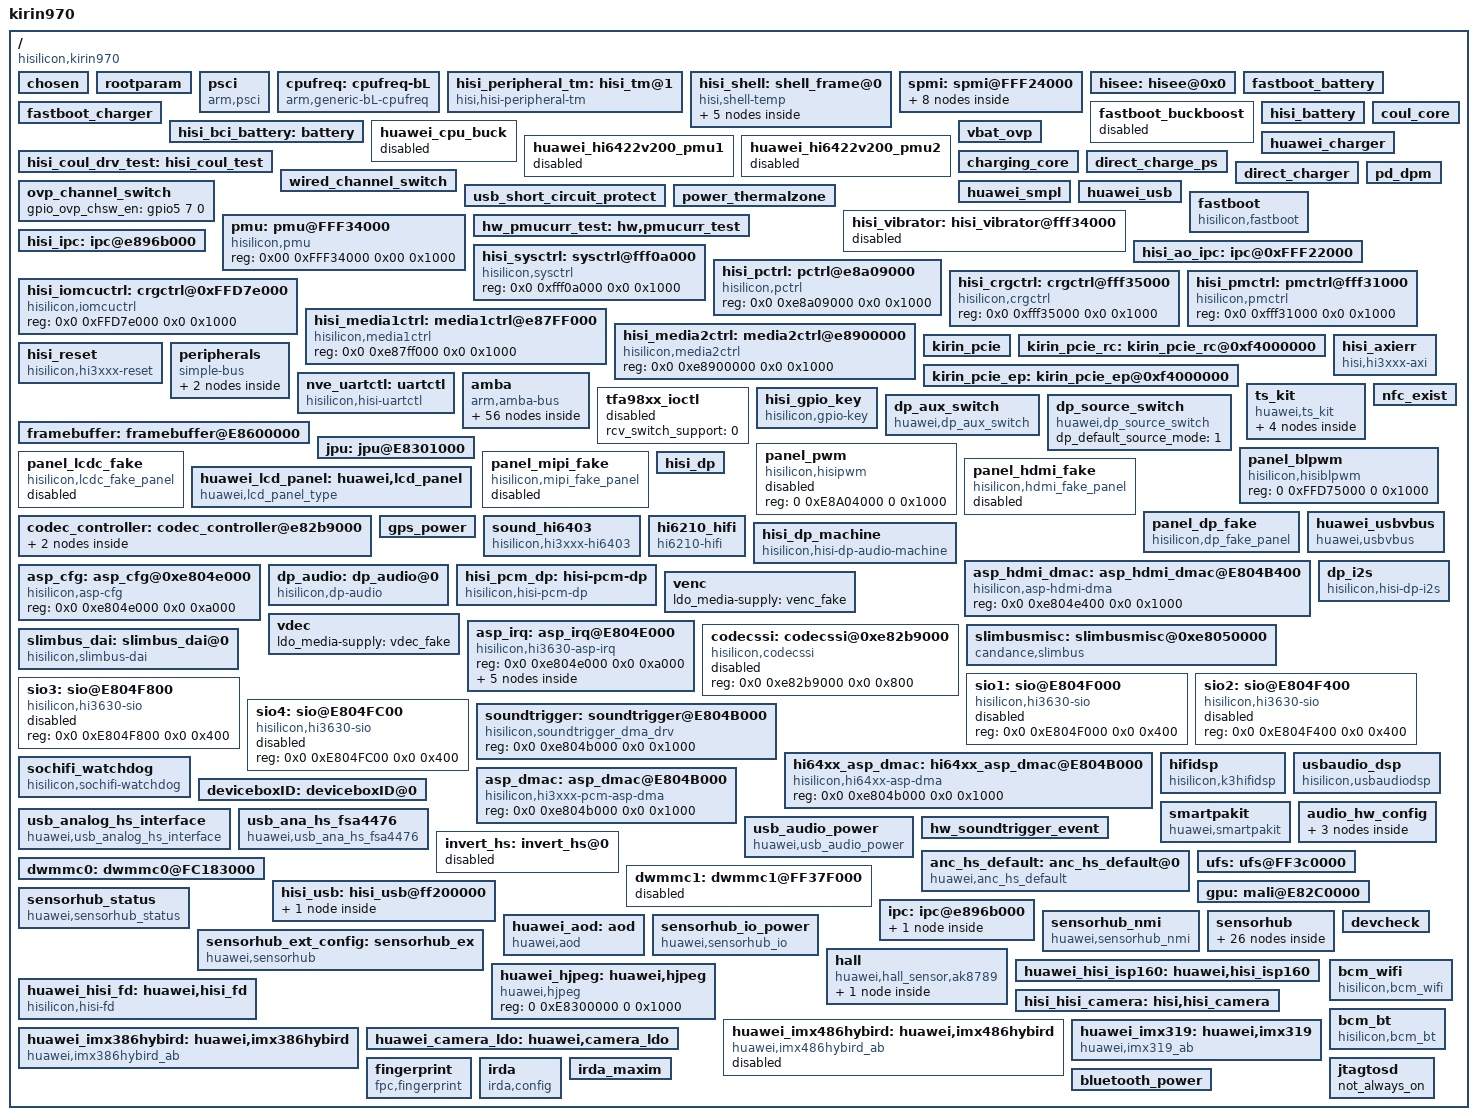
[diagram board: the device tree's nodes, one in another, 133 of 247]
/**
 * Copyright (C) 2014 Hisilicon Ltd.
 *
 *  This program is free software; you can redistribute it and/or modify
 *  it under the terms of the GNU General Public License version 2 as
 *  publishhed by the Free Software Foundation.
 */

/dts-v1/;
/include/ "fastboot.dtsi"
/include/ "BLANC_TUGL_V1_pin.dtsi"
/include/ "kirin970_cci.dtsi"
/include/ "kirin970_gic.dtsi"
/include/ "kirin970_timer.dtsi"
/include/ "kirin970_clock_cs.dtsi"
/include/ "kirin970_peri_dvfs_volt_cs.dtsi"
/include/ "kirin970_peri_dvfs_cs.dtsi"
/include/ "kirin970_isp_cs.dtsi"
/include/ "kirin970_powerip_cs.dtsi"
/include/ "hisi_freq_autodown.dtsi"
/include/ "kirin970.dtsi"
/include/ "kirin970_lowpm.dtsi"
/include/ "kirin970_i2c.dtsi"
/include/ "kirin970_gpio_cs.dtsi"
/include/ "kirin970_pinctrl_cs.dtsi"
/include/ "hisi_64xx_codec.dtsi"
/include/ "BLANC_TUGL_V1_hi6402_pin.dtsi"
/include/ "huawei_pmucurr_test.dtsi"
/include/ "hisi_bci_battery.dtsi"
/include/ "hisi_battery.dtsi"
/include/ "huawei_charger.dtsi"
/include/ "hisi_coul_spmi.dtsi"
/include/ "kirin970_soft_isc.dtsi"
/include/ "fastboot_battery.dtsi"
/include/ "fastboot_charger.dtsi"
/include/ "usb_short_circuit_protect.dtsi"
/include/ "desayatl_3900_39k_4400.dtsi"
/include/ "scudlg_3900_200k_4400_25.dtsi"
/include/ "sunwodasony_3900_110k_4400_15.dtsi"
/include/ "kirin970_thermal.dtsi"
/include/ "kirin970_pd.dtsi"
/include/ "fastboot_charger.dtsi"
/include/ "hisi_power_ip_test.dtsi"
/include/ "kirin970_framebuffer.dtsi"
/include/ "hisi_6421v600_pmic_led_spmi.dtsi"
/include/ "kirin970_coresight.dtsi"
/include/ "hisi_rtc_spmi.dtsi"
/include/ "modem/hisi_modem_balong.dtsi"
/include/ "hisi_soundtrigger_event.dtsi"
/include/ "huawei_audio.dtsi"
/include/ "huawei_smartpa.dtsi"
/include/ "kirin970_noc.dtsi"
/include/ "kirin970_dma64.dtsi"
/include/ "huawei_gps.dtsi"
/include/ "kirin970_trustedcore.dtsi"
/include/ "kirin970_jpu.dtsi"
/include/ "kirin970_ics_cs.dtsi"
/include/ "kirin970_perfstat_cs.dtsi"
/include/ "kirin970_cpu_cs.dtsi"
/include/ "huawei_connectivity.dtsi"
/include/ "huawei_devdetect.dtsi"
/include/ "huawei_hall_inputhub.dtsi"
/include/ "huawei_irda.dtsi"
/include/ "huawei_usbpd.dtsi"
/include/ "huawei_usb_vbus.dtsi"
/include/ "huawei_bluetooth.dtsi"
/include/ "hisi_sim_hotplug.dtsi"
/include/ "lcdkit/default/devkit_lcd.dtsi"
/include/ "lcdkit/blanc_tugl/devkit_lcd.dtsi"
/include/ "huawei_usbswitch.dtsi"
/include/ "huawei_bastet.dtsi"

/ {
	#address-cells = <2>;
	#size-cells = <2>;
	model = "kirin970";
	compatible = "hisilicon,kirin970";
	interrupt-parent = <&gic>;
	hisi,boardid = <6 4 5 0>;
	hisi,boardname = "BLANC_TUGL_V1";
	hisi,modem_id = <0x39010000>;
	hisi,product_id = <0x39010000>;
	hisi,product_name = "BLANC-AL00";
	hisi,camera_arch_csudp = "platform_cs_udp";

	chosen: chosen {};

	rootparam: rootparam {
	};


	psci: psci {
                compatible      = "arm,psci";
        };

	/* cpufreq  device */
	cpufreq: cpufreq-bL {
		compatible = "arm,generic-bL-cpufreq";
		status = "ok";
	};

	hisi_peripheral_tm: hisi_tm@1 {
		compatible = "hisi,hisi-peripheral-tm";
		hisi,peripheral_sensors = <8>;

		hisi,detect_system_h_tm_chanel = <7>;
		hisi,detect_system_h_tm_ntc = "austin_hkadc_soc_temp_table";
		hisi,detect_system_h_tm_state = "enable";
		hisi,detect_system_h_throttling = <53>;
		hisi,detect_system_h_shutdown = <55>;
		hisi,detect_system_h_below_vr_min = <53>;
		hisi,detect_system_h_over_skin = <12>;

		hisi,detect_flash_led_tm_chanel = <3>;
		hisi,detect_flash_led_tm_ntc = "austin_hkadc_soc_temp_table";
		hisi,detect_flash_led_tm_state = "enable";

		hisi,detect_charger_tm_chanel = <5>;
		hisi,detect_charger_tm_ntc = "austin_hkadc_soc_temp_table";
		hisi,detect_charger_tm_state = "enable";

		hisi,detect_pa_0_tm_chanel = <4>;
		hisi,detect_pa_0_tm_ntc = "austin_hkadc_pa_temp_table";
		hisi,detect_pa_0_tm_state = "enable";

		hisi,detect_pa_1_tm_chanel = <9>;
		hisi,detect_pa_1_tm_ntc = "austin_hkadc_pa_temp_table";
		hisi,detect_pa_1_tm_state = "enable";

		hisi,detect_dcxo0_tm_chanel = <15>;
		hisi,detect_dcxo0_tm_ntc = "austin_hkadc_adc_temp_table";
		hisi,detect_dcxo0_tm_state = "enable";

		hisi,detect_shell_tm_chanel = <7>;
		hisi,detect_shell_tm_ntc = "austin_hkadc_soc_temp_table";
		hisi,detect_shell_tm_state = "disable";

		hisi,detect_charger1_tm_chanel = <4>;
		hisi,detect_charger1_tm_ntc = "austin_hkadc_soc_temp_table";
		hisi,detect_charger1_tm_state = "disable";

		status = "ok";
	};

	hisi_shell: shell_frame@0 {
		compatible = "hisi,shell-temp";
		interval = <5000>;
		bias = <50000>;
		count = <6>;
		status = "ok";

		sensors {
			sensor0 {
				type = "system_h";
				coef = "15157","5997","4051","4534","8584","30816";
			};

			sensor1 {
				type = "charger";
				coef = "-761","-2276","-3227","-1293","-2952","-10036";
			};

			sensor2 {
				type = "pa_0";
				coef = "30555","9209","7077","8095","10650","28721";
			};

			sensor3 {
				type = "dcxo0";
				coef = "-5456","-5990","-6211","-6711","-9098","-17481";
			};
		};
	};

	spmi: spmi@FFF24000 {
		pmic: pmic@0 {
			pmic_led: pmic_led@a0 {
				status = "ok";
			};

			pmic_rtc: pmic_rtc@a0 {
				status = "ok";
			};

			ponkey: ponkey@b1 {
				status = "ok";
			};

			pmic_mntn: pmic_mntn@a0 {
				status = "ok";
			};

			hi6421v600_coul_spmi: hi6421v600_coul_spmi@1 {
                                 status = "ok";
                        };
		};
	};

	hisee: hisee@0x0 {
	};

	fastboot_battery: fastboot_battery {
		status = "ok";
	};

	fastboot_charger: fastboot_charger {
		status = "ok";
	};

	fastboot_buckboost: fastboot_buckboost {
		status = "disabled";
	};

	hisi_battery: hisi_battery {
		status = "ok";
	};

	hisi_bci_battery: battery {
		status = "ok";
	};

	coul_core: coul_core {
		status = "ok";
	};

	huawei_cpu_buck: huawei_cpu_buck {
		status = "disabled";
	};

	huawei_hi6422v200_pmu1: huawei_hi6422v200_pmu1 {
		status = "disabled";
	};

	huawei_hi6422v200_pmu2: huawei_hi6422v200_pmu2 {
		status = "disabled";
	};

	hisi_coul_drv_test: hisi_coul_test {
		status = "ok";
	};

	huawei_charger: huawei_charger {
		status = "ok";
	};

	vbat_ovp: vbat_ovp {
		status = "ok";
	};

	charging_core: charging_core {
		status = "ok";
		iterm = <160>;
		iin_usb = <470>;
		ichg_usb = <500>;
		ichg_fcp = <3500>;
		iin_fcp = <2000>;
		ichg_ac = <2100>;
		iin_ac = <2000>;
		inductance_para =
			"-32767", "15", "1900", "0",
			"15", "32767", "1900", "0";
	};
	direct_charge_ps: direct_charge_ps {
		boost_5v_support_scp_power = <1>;
		bst_ctrl_use_common_gpio = <1>;
		is_need_bst_ctrl = <1>;
		status = "ok";
	};
	direct_charger: direct_charger{
		use_5A = <1>;
		volt_para =
			"4100", "5150", "4650",
			"4250", "4650", "2800",
			"4360", "2800", "1200";
		compensate_r = <20>;
		cc_cable_detect_enable = <1>;
		full_path_res_max = <140>;
		scp_work_on_charger = <1>;
		standard_cable_full_path_res_max = <200>;
		temp_para =
			"-32767", "10", "0",
			"10", "45", "5150",
			"45", "32767", "0";
		status = "ok";
	};
	wired_channel_switch: wired_channel_switch {
		status = "ok";
	};
	ovp_channel_switch: ovp_channel_switch {
		gpio_ovp_chsw_en = <&gpio5 7 0>;
		status = "ok";
	};
	huawei_smpl: huawei_smpl {
		status = "ok";
	};

	usb_short_circuit_protect: usb_short_circuit_protect {
		status = "ok";
	};

	power_thermalzone: power_thermalzone {
		status = "ok";
	};

	pd_dpm: pd_dpm {
		uart_use_sbu = <1>;
		uart_rx_gpio = <&gpio4 5 0>;
		uart_tx_gpio = <&gpio4 6 0>;
		abnormal_cc_detection = <1>;
		status = "ok";
	};

	huawei_usb: huawei_usb {
		status = "ok";
	};

	hisi_vibrator: hisi_vibrator@fff34000 {
		status = "disabled";
	};

	fastboot: fastboot {
		compatible = "hisilicon,fastboot";
	};

	pmu: pmu@FFF34000 {
		compatible = "hisilicon,pmu";
		reg = <0x00 0xFFF34000 0x00 0x1000>;
		status = "ok";
	};

	hw_pmucurr_test: hw,pmucurr_test {
		status = "ok";
	};

	hisi_ipc: ipc@e896b000 {
		status = "ok";
	};

	hisi_ao_ipc: ipc@0xFFF22000 {
		status = "ok";
	};

        hisi_sysctrl: sysctrl@fff0a000 {
                compatible = "hisilicon,sysctrl";
                reg = <0x0 0xfff0a000 0x0 0x1000>;
                status = "ok";
        };

        hisi_pctrl: pctrl@e8a09000 {
                compatible = "hisilicon,pctrl";
                reg = <0x0 0xe8a09000 0x0 0x1000>;
                status = "ok";
        };

        hisi_crgctrl: crgctrl@fff35000 {
                compatible = "hisilicon,crgctrl";
                reg = <0x0 0xfff35000 0x0 0x1000>;
                status = "ok";
        };

        hisi_iomcuctrl: crgctrl@0xFFD7e000 {
                compatible = "hisilicon,iomcuctrl";
                reg = <0x0 0xFFD7e000 0x0 0x1000>;
                status = "ok";
	};

        hisi_pmctrl: pmctrl@fff31000 {
                compatible = "hisilicon,pmctrl";
                reg = <0x0 0xfff31000 0x0 0x1000>;
                status = "ok";
        };

        hisi_media1ctrl: media1ctrl@e87FF000 {
                compatible = "hisilicon,media1ctrl";
                reg = <0x0 0xe87ff000 0x0 0x1000>;
                status = "ok";
        };

        hisi_media2ctrl: media2ctrl@e8900000 {
                compatible = "hisilicon,media2ctrl";
                reg = <0x0 0xe8900000 0x0 0x1000>;
                status = "ok";
        };

	kirin_pcie: kirin_pcie {
	};

	kirin_pcie_rc: kirin_pcie_rc@0xf4000000 {
		reg =  <0x0 0xf4000000 0x0 0x1000000>, <0x0 0xfc180000 0x0 0x1000>, <0x0 0xfc000000 0x0 0x80000>, <0x0 0xF4000000 0 0x2000>;
		status = "ok";
	};

	kirin_pcie_ep: kirin_pcie_ep@0xf4000000 {
		reg =  <0x0 0xf4000000 0x0 0x1000000>, <0x0 0xfc180000 0x0 0x1000>, <0x0 0xfc000000 0x0 0x80000>, <0x0 0xF4000000 0 0x2000>;
	};

	hisi_axierr: hisi_axierr {
	        compatible = "hisi,hi3xxx-axi";
	        status = "ok";
        };

	hisi_reset: hisi_reset {
		compatible = "hisilicon,hi3xxx-reset";
		status = "ok";
	};

	peripherals: peripherals {
		compatible = "simple-bus";
		ranges = <0x0 0x00000000 0x0 0xffffffff>;

		clk6250khz: clk6250khz {
			compatible = "fixed-clock";
		};
/*
		clk4800khz: clk4800khz {
			compatible = "fixed-clock";
		};
*/
		dma0: dma@fdf30000 {
			status = "ok";
		};
	};

	nve_uartctl: uartctl {
		compatible = "hisilicon,hisi-uartctl";
	};

	amba: amba {
		compatible = "arm,amba-bus";
		ranges;

		/*rtc0: rtc@FFF04000 {
				compatible = "arm,rtc-pl031", "arm,primecell";
				reg = <0xfff04000 0x1000>;
				status = "ok";
		};*/

		/*rtc1: rtc@FFF05000 {
				compatible = "arm,rtc-pl031", "arm,primecell";
				reg = <0xfff05000 0x1000>;
				status = "ok";
		};*/

		watchdog0 {
			compatible = "arm,sp805", "arm,primecell";
			reg = <0x0 0xe8a06000 0x0 0x1000>;
			default-timeout = <24>;
			interrupts = <0 44 4>;
			clocks = <&pclk_gate_wd0 &pclk>;
			clock-names = "pclk_wd0", "apb_pclk";
			status = "ok";
		};

                iomcu_watchdog: watchdog@ffd7c000 {
                        compatible = "hisilicon,iomcu-watchdog";
                        reg = <0x0 0xFFD7C000 0x0 0x1000>;
                        status = "ok";
                };

		/*wdt1@e8a07000 {
			compatible = "arm,sp805", "arm,primecell";
			reg = <0x0 0xe8a07000 0x0 0x1000>;
		};*/

		serial0: uart@fdf02000 {
			status = "ok";
		};

		serial1: uart@fdf00000 {
			status = "disabled";
		};

		serial2: uart@fdf03000 {
			status = "ok";
		};

		serial3: uart@ffd74000 {
			status = "disabled";
		};

		serial4: uart@fdf01000 {
			status = "ok";
		};

		serial5: uart@fdf05000 {
			status = "ok";
		};

		serial6: uart@fff32000 {
			status = "ok";
		};

		dx_cc63p: dx_cc63p@fdf0e000 {
			compatible = "dx,cc63p";
			reg = <0x0 0xfdf0e000 0x0 0x1000>;
			status = "ok";
		};

		spi0: spi@ffd70000 {
			status = "disabled";

			spi_dev0: spi_dev0@0 {
				compatible = "spi_dev0";
				reg = <0>;
			};

			spi_dev1: spi_dev1@1 {
				compatible = "spi_dev1";
				reg = <1>;
			};

			spi_dev2: spi_dev2@2 {
				compatible = "spi_dev2";
				reg = <2>;
			};

			spi_dev3: spi_dev3@3 {
				compatible = "spi_dev3";
				reg = <3>;
			};
		};

		spi1: spi@fdf08000 {
			status = "disabled";

			spi_dev10: spi_dev10@10 {
				compatible = "spi_dev10";
				reg = <0>;
			};
		};

		spi3: spi@fff2a000 {
			status = "ok";
			hardware-mutex = <0x01>;
			smc-flag = <0x01>;
			clock-rate = <83000000>;
			pinctrl-names = "default", "idle";
			pinctrl-0 = <&gpio144_pmx_func &gpio145_pmx_func &gpio146_pmx_func &gpio144_cfg_func &gpio145_cfg_func
					&gpio146_cfg_func>;
			pinctrl-1 = <&gpio144_pmx_idle &gpio145_pmx_idle &gpio146_pmx_idle &gpio144_cfg_idle &gpio145_cfg_idle
					&gpio146_cfg_idle>;
			huawei_thp: huawei_thp@10 {
					status = "disabled";
					compatible = "huawei,thp";
					spi-max-frequency = <10000000>;
					reg = <0>;
					pl022,com-mode = <2>;
					pl022,interface = <0>;
					pl022,rx-level-trig = <3>;
					pl022,tx-level-trig = <3>;
					pl022,ctrl-len = <7>;
					pl022,wait-state = <0>;
					pl022,duplex = <0>;
					pl022,slave-tx-disable = <0>;
					irq_gpio = <&gpio26 4 0>;
					cs_gpio = <&gpio18 3 0>;
					rst_gpio = <&gpio1 7 0>;
					boot_reset_hi_delay_ms = <1>;
					boot_reset_low_delay_ms = <0>;
					boot_reset_after_delay_ms = <0>;
					resume_reset_after_delay_ms = <1>;
					suspend_reset_after_delay_ms = <0>;
					spi_sync_cs_hi_delay_ns = <200>;
					spi_sync_cs_low_delay_ns = <10>;
					thp_input_dev {
						compatible = "huawei,thp_input";
						abs_max_x = <1440>;
						abs_max_y = <2560>;
					};
					novatech {
						spi_sync_cs_hi_delay_ns = <200>;
						spi_sync_cs_low_delay_ns = <200>;
					};
					rohm-bu21150 {
						pl022,com-mode = <0>;
						spi_sync_cs_hi_delay_ns = <200>;
						spi_sync_cs_low_delay_ns = <10>;
					};
			};

			spi_dev30: spi_dev30@30 {
				compatible = "spi_dev30";
				reg = <0>;
			};

			spi_dev31: spi_dev31@31 {
				compatible = "spi_dev31";
				reg = <1>;
			};

			spi_dev32: spi_dev32@32 {
				compatible = "spi_dev32";
				reg = <2>;
			};

			spi_dev33: spi_dev33@33 {
				compatible = "spi_dev33";
				reg = <3>;
			};
		};
		/* I2C0 ~ I2C4 */
		i2c0: i2c@FFD71000 {
			status = "disabled";
		};

		i2c1: i2c@FFD72000 {
			status = "ok";

			fusb30x_i2c1@22 {
				status = "ok";
			};

			rt1711_i2c1@4e {
				status = "ok";
			};

			tusb422_i2c1@20 {
				status = "ok";
			};

			rt9748: rt9748@67 {
				compatible = "rt9748";
				reg = <0x67>;
				status = "ok";
			};
		};

		i2c2: i2c@FFD73000 {
			status = "disabled";
		};

		i2c3: i2c@FDF0C000 {
			status = "ok";

			ti,lm36274 {
				compatible = "ti,lm36274";
				status = "disable";
			};

			ti,lp8556{
				compatible = "ti,lp8556";
				status = "disable";
			};

			ti,lm36923 {
				compatible = "ti,lm36923","ti,lm36923_i2c3";
				reg = <0x36>;
				status = "disable";
			};

			max77813: max77813@18 {
				compatible = "max77813";
				reg = <0x18>;
				status = "disabled";
			};

			huawei,vl53l0@29 {
				compatible = "huawei,vl53l0_970";
				reg = <0x29>;
				status = "ok";
			};
		};

		i2c4: i2c@FDF0D000 {
			status = "ok";

			ti-drv2605@5a {
				status = "ok";
				reg = <0x5a>;
				compatible = "ti,drv2605";
			};

			tfa9872_smartpa_l:smartpa@35 {
				compatible = "huawei,smartpakit_i2c";
				/* 0 MAXIM, 1 NXP, 2 TI, 3 OTHER */
				chip_vendor = <1>;
				/* refer to smartpakit.out_device prop */
				chip_id = <0>;
				chip_model = "tfa9872";
				status = "ok";

				/* reg_ctl node: a node contains three data<addr value ctl_type>
				 * ctl_type: 0 read reg(default), 1 write reg, 2 only time delay
				 * value:
				 *     read:  reg number(num >= 1)
				 *     write: reg value
				 *     delay: time delay
				 * time delay unit: msecs */
				version_regs = <0x03 1 0>;
				dump_regs = <0 256 0>;
				hw_reset {
					gpio_reset = <&gpio16 6 0>;
					/* gpio_state node: a node contains two data<state delay>
					 * time delay unit: msecs */
					ctl_sequence = <1 1 0 1>;
				};
				irq_handler {
					gpio_irq = <&gpio16 2 0>;
					/* 0x0 IRQF_TRIGGER_NONE, 0x1 IRQF_TRIGGER_RISING, 0x2 IRQF_TRIGGER_FALLING, 0x4 IRQF_TRIGGER_HIGH, 0x8 IRQF_TRIGGER_LOW*/
					irq_flags = <2>;
					/* whether or not need reset chip*/
					need_reset;
					rw_sequence = <
						0x10 1 0
						0x11 1 0
						0x13 1 0
						0x14 1 0
						0x40 1 0
						0x41 1 0
						0x42 1 0
					>;
				};
				regmap_cfg {
					reg_bits = <8>;
					val_bits = <16>;
					/* 0 REGCACHE_NONE, 1 REGCACHE_RBTREE, 2 REGCACHE_COMPRESSED, 3 REGCACHE_FLAT */
					cache_type = <0>;
					max_register = <0xff>;
					// reg_writeable = <>;
					// reg_unwriteable = <>;
					// reg_readable = <>;
					// reg_unreadable = <>;
					// reg_volatile = <>;
					// reg_unvolatile = <>;
					reg_defaults = <
						0x00 0x1801
						0x01 0x0014
					>;
				};
			};

			tfa9872_smartpa_r:smartpa@36 {
				compatible = "huawei,smartpakit_i2c";
				/* 0 MAXIM, 1 NXP, 2 TI, 3 OTHER */
				chip_vendor = <1>;
				/* refer to smartpakit.out_device prop */
				chip_id = <1>;
				chip_model = "tfa9872";
				status = "ok";

				/* reg_ctl node: a node contains three data<addr value ctl_type>
				 * ctl_type: 0 read reg(default), 1 write reg, 2 only time delay
				 * value:
				 *     read:  reg number(num >= 1)
				 *     write: reg value
				 *     delay: time delay
				 * time delay unit: msecs */
				version_regs = <0x03 1 0>;
				dump_regs = <0 256 0>;
				hw_reset {
					gpio_reset = <&gpio16 7 0>;
					/* gpio_state node: a node contains two data<state delay>
					 * time delay unit: msecs */
					ctl_sequence = <1 1 0 1>;
				};
				irq_handler {
					gpio_irq = <&gpio16 1 0>;
					/* 0x0 IRQF_TRIGGER_NONE, 0x1 IRQF_TRIGGER_RISING, 0x2 IRQF_TRIGGER_FALLING, 0x4 IRQF_TRIGGER_HIGH, 0x8 IRQF_TRIGGER_LOW*/
					irq_flags = <2>;
					/* whether or not need reset chip*/
					need_reset;
					rw_sequence = <
						0x10 1 0
						0x11 1 0
						0x13 1 0
						0x14 1 0
						0x40 1 0
						0x41 1 0
						0x42 1 0
					>;
				};
				regmap_cfg {
					reg_bits = <8>;
					val_bits = <16>;
					/* 0 REGCACHE_NONE, 1 REGCACHE_RBTREE, 2 REGCACHE_COMPRESSED, 3 REGCACHE_FLAT */
					cache_type = <0>;
					max_register = <0xff>;
					// reg_writeable = <>;
					// reg_unwriteable = <>;
					// reg_readable = <>;
					// reg_unreadable = <>;
					// reg_volatile = <>;
					// reg_unvolatile = <>;
					reg_defaults = <
						0x00 0x1801
						0x01 0x0014
					>;
				};
			};

			pn547_nfc: nfc@28{
				status = "ok";
				reg = <0x28>;
				compatible = "hisilicon,pn547_nfc";
			};

			huawei,lm3646@67 {
				status = "ok";
			};

			huawei,mp3336@27 {
				status = "ok";
			};
		};

		i2c6: i2c@FFD6A000 {
			status = "ok";

			hi6523_charger_i2c6: hi6523_charger_i2c6@6B {
				status = "ok";
				fcp_support = <1>;
				scp_support = <1>;
				vclamp = <150>;
				bat_comp = <30>;
				gpio_int = <&gpio18 6 0>;
				ico_current_mode = <0>;
			};
			fairchild_fsa9685_i2c6: fsa9685_i2c6@25{
				usbid-enable = <0>;
				scp_support = <1>;
				fairchild_fsa9685,gpio-intb = <&gpio28 3 0>;
				status = "disabled";
			};
		};

		i2c7: i2c@FDF0B000 {
			status = "ok";
		};
	};
	/* end amba */

	/*ts kit*/
	ts_kit: ts_kit {
		compatible = "huawei,ts_kit";

		sec_ts: touchscreen@90 {
			compatible = "sec_ts";
			i2c_address = <0x17>;
			ic_type = <0>; /* oncell */
			algo_id = <1>;
			charger_notify_gpio = <&gpio16 4 0>;
			y_max_mt = <2160>;
			x_max_mt = <1080>;
			y_max = <2160>;
			x_max = <1080>;
			irq_config = <0>;
			raw_data_limit =	"507", "248", /* mutual raw cap max min*/
						"60", "60", /* mutual raw cap gap col max raw max*/
						"40", "-40", /* mutual detla max min*/
						"-800", "-2400", /* self raw cap long(rx) max min*/
						"-800", "-2600", /* self raw cap short(tx) max min*/
						"999999", "-999999", /* self detla long(rx) max min*/
						"999999", "-999999"; /* self detla short(tx) max min*/
			cal_data_limit = "99999", "99999", "99999";
			sec_ts-dvdd-supply = <&ldo16>;
			sec_ts-avdd-supply = <&ldo9>;
			dvdd_value = <1850000>;
			avdd_value = <3300000>;
			i2c-burstmax = <256>;
			max_x = <1079>;
			max_y = <2159>;
			vddio_regulator_type = <1>;
			vddio_gpio_type = <0>;
			vddio_ctrl_gpio = <&gpio8 3 0>;
			vci_regulator_type = <1>;
			vci_gpio_type = <0>;
			vci_ctrl_gpio = <&gpio8 3 0>;
			supported_func_indicater = <1>;
			charger_supported = <1>;
			tp_test_type = "Normalize_type:judge_different_reslut";
			BLAC570900 {
				compatible = "sec_ts-BLAC570900";
			};
		};
		synaptics: touchscreen@70 {
			compatible = "synaptics";
			BLAC501100 {
				producer = "Tianma";
				compatible = "synaptics-BLAC501100";
			};
		};
	};

	nfc_exist: nfc_exist {
		status = "ok";
	};

	tfa98xx_ioctl: tfa98xx_ioctl {
		rcv_switch_support = <0>;
		status = "disabled";
	};

	hisi_gpio_key: hisi_gpio_key {
		compatible = "hisilicon,gpio-key";
		status = "ok";
	};

	dp_aux_switch: dp_aux_switch {
	        compatible = "huawei,dp_aux_switch";
	        status = "ok";
	};

        /*set dp source default mode*/
        dp_source_switch {
                compatible = "huawei,dp_source_switch";
                dp_default_source_mode = <1>; /*0:diff mode 1:same mode*/
                status = "ok";
        };

	/* display start */
	framebuffer: framebuffer@E8600000 {
	};

	/*jpeg decode */
	jpu: jpu@E8301000 {
	};

	panel_pwm: panel_pwm {
		compatible = "hisilicon,hisipwm";
		reg = <0 0xE8A04000 0 0x1000>;
		status = "disabled";
	};

	panel_blpwm: panel_blpwm {
		compatible = "hisilicon,hisiblpwm";
		reg = <0 0xFFD75000 0 0x1000>;
		status = "ok";
	};

	panel_lcdc_fake: panel_lcdc_fake {
		compatible = "hisilicon,lcdc_fake_panel";
		status = "disabled";
	};

	panel_mipi_fake: panel_mipi_fake {
		compatible = "hisilicon,mipi_fake_panel";
		status = "disabled";
	};

	huawei_lcd_panel: huawei,lcd_panel {
		compatible = "huawei,lcd_panel_type";
	};

	panel_hdmi_fake: panel_hdmi_fake {
		compatible = "hisilicon,hdmi_fake_panel";
		status = "disable";
	};

	panel_dp_fake: panel_dp_fake {
		compatible = "hisilicon,dp_fake_panel";
		status = "ok";
	};

	hisi_dp {
		preemphasis_swing = <0x3c0>, <0x9788>, <0x2040>, <0xA188>, <0x2640>, <0xA598>, <0x2c40>, <0xA1F8>, <0x3040>,
			<0xA388>, <0x2040>, <0xA9A0>, <0x2840>, <0xA5F8>, <0x2C40>, <0xAFA0>, <0x2040>, <0xA9F8>, <0X2840>, <0xB1F8>, <0x2040>;
		status = "ok";
	};

	huawei_usbvbus: huawei_usbvbus {
		compatible = "huawei,usbvbus";
		status = "ok";
	};

	/* display end */

	/* audio device beg */
	codec_controller: codec_controller@e82b9000 {
		slimbusclk_io_driver = <0x2>;
		slimbusdata_io_driver = <0x2>;
		status = "ok";

		hi64xx_irq: hi64xx_irq@0 {
			status = "ok";

			hi6403_codec: hi6403_codec@0 {
				status = "ok";
			};
		};
	};

	gps_power: gps_power {
		status = "ok";
	};

	sound_hi6403: sound_hi6403 {
		compatible = "hisilicon,hi3xxx-hi6403";
		status = "ok";
	};

	hi6210_hifi: hi6210_hifi {
		compatible = "hi6210-hifi";
		status = "ok";
	};

	hisi_dp_machine: hisi_dp_machine {
		compatible = "hisilicon,hisi-dp-audio-machine";
		status = "ok";
	};

	asp_hdmi_dmac: asp_hdmi_dmac@E804B400 {
		compatible = "hisilicon,asp-hdmi-dma";
		reg = <0x0 0xe804e400 0x0 0x1000>;
		status = "ok";
	};

	asp_cfg: asp_cfg@0xe804e000 {
		compatible = "hisilicon,asp-cfg";
		reg = <0x0 0xe804e000 0x0 0xa000>;
		status = "ok";
	};

	dp_i2s: dp_i2s {
		compatible = "hisilicon,hisi-dp-i2s";
		status = "ok";
        };

	dp_audio: dp_audio@0 {
		compatible = "hisilicon,dp-audio";
		status = "ok";
        };

	hisi_pcm_dp: hisi-pcm-dp {
		compatible = "hisilicon,hisi-pcm-dp";
		status = "ok";
	};
	venc {
		ldo_media-supply = <&venc_fake>;
	};
	vdec {
		ldo_media-supply = <&vdec_fake>;
	};

	asp_irq: asp_irq@E804E000 {
		compatible = "hisilicon,hi3630-asp-irq";
		reg = <0x0 0xe804e000 0x0 0xa000>;

		asp_common@0 {
			compatible = "hisilicon,hi3630-asp-common";
		};

		asp_srcup_normal@0 {
			compatible = "hisilicon,hi3630-srcup-normal";
		};

		asp_srcup_dsp@0 {
			compatible = "hisilicon,hi3630-srcup-dsp";
		};

		asp_srcdown@0 {
			compatible = "hisilicon,hi3630-srcdown";
		};

		asp_hdmi@0 {
			compatible = "hisilicon,hi3630-pcm-hdmi";
		};
	};

	codecssi: codecssi@0xe82b9000 {
		compatible = "hisilicon,codecssi";
		reg = <0x0 0xe82b9000 0x0 0x800>;
		status = "disabled";
	};

	slimbusmisc: slimbusmisc@0xe8050000 {
		compatible = "candance,slimbus";
		reg = <0x0 0xe8050000 0x0 0xb00>,
			<0x0 0xe804e000 0x0 0xa000>,
			<0x0 0xfff0a000 0x0 0x1000>;
		interrupts = <0x0 0x96 0x4>;
		interrupt-names = "asp_irq_slimbus";
		slimbus-reg-supply = <&asp>;
		pinctrl-names = "default", "idle";
		pinctrl-0 = <&gpio192_pmx_func
				&gpio193_pmx_func
				&gpio192_cfg_func
				&gpio193_cfg_func>;
		pinctrl-1 = <&gpio192_pmx_idle
				&gpio193_pmx_idle
				&gpio192_cfg_idle
				&gpio193_cfg_idle>;
		slimbus-ssi-sel = "slimbus";
		asp_power_state_offset = <0x06c>;
		slimbusclk_offset = <0x038>;
		slimbusdata_offset = <0x03c>;
		slimbusclk_cfg_offset = <0x864>;
		slimbusdata_cfg_offset = <0x868>;
		platform-type   = "ASIC";
		codec-type = "slimbus-6403cs";
		clk_asp_subsys = <415000>;
		slimbus_dynamic_freq= "true";
		pm_runtime_support;
		status = "ok";
	};

	slimbus_dai: slimbus_dai@0 {
		compatible = "hisilicon,slimbus-dai";
		status = "ok";
	};

	sio1: sio@E804F000 {
		compatible = "hisilicon,hi3630-sio";
		reg = <0x0 0xE804F000 0x0 0x400>;
		status = "disabled";
	};

	sio2: sio@E804F400 {
		compatible = "hisilicon,hi3630-sio";
		reg = <0x0 0xE804F400 0x0 0x400>;
		status = "disabled";
	};

	sio3: sio@E804F800 {
		compatible = "hisilicon,hi3630-sio";
		reg = <0x0 0xE804F800 0x0 0x400>;
		status = "disabled";
	};

	sio4: sio@E804FC00 {
		compatible = "hisilicon,hi3630-sio";
		reg = <0x0 0xE804FC00 0x0 0x400>;
		status = "disabled";
	};

	soundtrigger: soundtrigger@E804B000 {
		compatible = "hisilicon,soundtrigger_dma_drv";
		reg = <0x0 0xe804b000 0x0 0x1000>;
		status = "ok";
	};

	hi64xx_asp_dmac: hi64xx_asp_dmac@E804B000 {
		compatible = "hisilicon,hi64xx-asp-dma";
		reg = <0x0 0xe804b000 0x0 0x1000>;
		status = "ok";
	};

	hifidsp: hifidsp {
		compatible = "hisilicon,k3hifidsp";
		status = "ok";
	};

	sochifi_watchdog: sochifi_watchdog {
		compatible = "hisilicon,sochifi-watchdog";
		status = "ok";
	};

	asp_dmac: asp_dmac@E804B000 {
		compatible = "hisilicon,hi3xxx-pcm-asp-dma";
		reg = <0x0 0xe804b000 0x0 0x1000>;
		status = "ok";
	};

        usbaudio_dsp: usbaudio_dsp {
                compatible = "hisilicon,usbaudiodsp";
                status = "ok";
        };

	deviceboxID: deviceboxID@0 {
		status = "ok";
	};

	smartpakit:smartpakit {
		compatible = "huawei,smartpakit";
		/* 0 hisi, 1 qcom */
		soc_platform = <0>;
		/* algo running on: 0 codec_dsp, 1 soc_dsp, 2 smartpa_dsp, 3 simple pa(not smpartpa), 4 simple pa(with i2c) */
		algo_in = <0>;
		/* algo_in params need match out_device for smartpa.
		 * Now, up to only support four pa, so out_device = <0 0 0 0>;
		 * 1. This array is arranged in the following order:
		 *    <0 1 2 3>
		 *    <pril prir secl secr>
		 * 2. This array element value is 0 or 1:
		 *    smartpa: 0 speaker, 1 receiver
		 *    simple pa: out_device not applicable, only set 0 to indicate pa_num
		 * 3. The length of this array is variable, for example:
		 *    single pa: out_device = <0>;
		 *    two pa: out_device = <0 0>;
		 *    four pa: out_device = <1 1 0 0>; */
		out_device = <0 1>;
		dsp_img_name = "hifi_6403_tfa_devkit.img";
		status = "ok";
	};

	usb_analog_hs_interface: usb_analog_hs_interface {
		compatible = "huawei,usb_analog_hs_interface";
		status = "ok";
	};

	usb_ana_hs_fsa4476: usb_ana_hs_fsa4476 {
		compatible = "huawei,usb_ana_hs_fsa4476";
		gpio_type = <0>;
		swtich_enn = <&gpio18 2 0>;
		swtich_en1 = <&gpio20 0 0>;
		swtich_en2 = <&gpio1 1 0>;
		mic_switch_delay = <150>;
		pd_unlock_enable = <1>; /* 0: disable; 1: enable */
		sd_gpio_used = <1>;
		status = "ok";
	};

	usb_audio_power: usb_audio_power {
		compatible = "huawei,usb_audio_power";
		gpio_type = <0>;
		gpio_chg_vbst_ctrl = <&gpio27 4 0>;
		gpio_ear_power_en = <&gpio26 1 0>;
		status = "ok";
	};

	audio_hw_config: audio_hw_config {
		product_name = "BLANC";
		multi_mic_enable = "true";
		vqm_enable = "true";
		spk_pa_name = "smartpakit";
		cust_name = "audio_custom";
		soc_name = "hi363x";
		codec_name = "hi6403";
		codec_dsp_algo = "mad";
		modem_sio_master = "false";
		asr_enable = "true";
		ear_pa_name = "smartpakit";
		analog_earpiece_enable = "false";
		status = "ok";
		audio_sar_support = "true";
		hifi_info {
			dsp_voice_vol_control = "1";/* 1 :need socdsp control volume; 0:platform codec */
		};

		hardware_info {
			status = "ok";
		};

		audio_capability {
			bwe_ui_support = "true";
			bwe_support = "true";
			swb_support = "true";
			wnr_support = "true";
			nv_evs_support = "true";
			lvm_support = "false";
			dhf_support = "true";
			voice_anc_support = "false";
			dual_smartpa_support = "true";
			stereo_handfree_support = "true";
			spk_rcv_stereo_support = "true";
			dual_smartpa_version = "2.0";
			earphone_multi_eq_support = "true";
			vdr_ui_support = "false";
			asr_vibrate_support = "true";
			mmi_capture_enable = "false";
			irda_support = "true";
			visualizer_support = "true";
			visualizer_frame = "Medium";
			/*
				sound trigger feature.
				false: this product doesn't support soundtrigger feature.
				2.0: this product supports the twice wakeup feature.
			*/
			soundtrigger_version = "2.0";
			/*
				max stream volume to replace Android default volume.
			*/
			max_stream_volume = "15";
		};
	};

	hw_soundtrigger_event: hw_soundtrigger_event {
		status = "ok";
	};

	invert_hs: invert_hs@0 {
		gpios = <&gpio26 0 0>;
		gpio_type = <0>;
		pinctrl-names = "default", "idle";
		pinctrl-0 = <&gpio208_pmx_func &gpio208_cfg_func>;
		pinctrl-1 = <&gpio208_pmx_idle &gpio208_cfg_idle>;
		status = "disabled";
	};

	anc_hs_default: anc_hs_default@0 {
		compatible = "huawei,anc_hs_default";
		status = "ok";
	};

	/* audio device end */

	/*bootdevice: bootdevice {
	};*/

	/* UFS */
	ufs: ufs@FF3c0000 {
		status = "ok";
	};

	/* eMMC 4.5 */
	dwmmc0: dwmmc0@FC183000 {
	};

	/* SD */
	dwmmc1: dwmmc1@FF37F000 {
		status = "disabled";
	};

	/* sdio */
	/*
	dwmmc2: dwmmc2@FC183000 {
		status = "disabled";
	};
	*/
	hisi_usb: hisi_usb@ff200000 {
		usb_ldo_disable = <1>;
		usb_aclk_freq = <238000000>;
		usb_support_dp = <1>;

		eye_diagram_param = <0x23DE7E7>;
		eye_diagram_host_param = <0x2FDE7E7>;
		usb_support_check_voltage = <0x1>;
		set_hi_impedance = <0x0>;
		dwc3@ff100000 {
		};
	};

	gpu: mali@E82C0000 {
		status = "ok";
	};

	sensorhub_status: sensorhub_status {
		compatible = "huawei,sensorhub_status";
		status= "ok";
	};

	ipc: ipc@e896b000 {	/* add for fpga because iom7 start too slow锛?300ms锛?*/
		mailbox-10 {
			timeout = <2000>;
		};
	};

	sensorhub_nmi: sensorhub_nmi {
		compatible = "huawei,sensorhub_nmi";
	};

	sensorhub: sensorhub {
		als_sensor: light {
			als1 {
				compatible="huawei,rohm_bh1745";
				reg=<0x38>;
				status = "ok";
			};

			als2 {
				compatible="huawei,avago_apds9251";
				reg=<0x52>;
				status = "ok";
			};
		};

		ps_sensor: proximity {
			ps1 {
				compatible="huawei,txc-pa224";
				reg=<0x1e>;
				chip_id_register=<0x7F>;
				chip_id_value=<0x11>;
				file_id=<39>;
				min_proximity_value=<180>;
				pwindows_value=<28>;
				pwave_value=<18>;
				threshold_value=<31>;
				gpio_int1=<&gpio27 1 0>;
				poll_interval = <80>;
				ps_oily_threshold = <2>;
				status = "ok";
			};

			ps2 {
				compatible="huawei,avago-apds9110";
				reg=<0x53>;
				chip_id_register=<0x6>;
				chip_id_value=<0xB1>;
				file_id=<49>;
				sensor_list_info_id = <0x04>;
				sensor_type="ps";
				min_proximity_value=<180>;
				pwindows_value=<25>;
				pwave_value=<19>;
				threshold_value=<27>;
				gpio_int1=<&gpio27 1 0>;
				poll_interval = <80>;
				ps_oily_threshold = <2>;
				status = "ok";
			};

		};

		acc_sensor: gsensor {
			acc1 {
				compatible ="huawei,st-lsm6dsm";
				reg =<0x6a>;
				status = "ok";
			};

			acc2 {
				compatible ="huawei,invensense-icm20690";
				reg =<0x68>;
				status = "ok";
			};
		};

		gyro_sensor: gyroscope {
			gyro1 {
				compatible ="huawei,st-lsm6dsm";
				reg =<0x6a>;
				status = "ok";
			};

			gyro2 {
				compatible ="huawei,inv-icm20690";
				reg =<0x68>;
				status = "ok";
			};
		};

		mag_sensor: compass {
			mag1 {
				compatible="huawei,akm-akm09911";
				reg=<0x0d>;
				chip_id_register=<0x00>;
				chip_id_value=<0x48>;
				file_id=<37>;
				sensor_list_info_id=<1>;
				sensor_type="mag";
				/*sensor-vdd-supply = <&ldo24>;*/
				outbit=<0>;
				softfilter = <2>;
				calibrate_method=<2>;
				axis_map_x=<0>;
				axis_map_y=<1>;
				axis_map_z=<2>;
				negate_x=<1>;
				negate_y=<0>;
				negate_z=<1>;
				poll_interval=<10>;
				gpio_int1=<&gpio0 0 0>;
				gpio_reset=<&gpio0 0 0>;
				softiron_parameter = <16 39 0 0 0 0 0 0 16 39 0 0 0 0 0 0 16 39 0 0 0 0 0 0 0 0 0>;
				sensorlist_name="mag-akm09911";
				vendor="akm";
				minDelay=<10000>;
				fifoReservedEventCount=<600>;
				fifoMaxEventCount=<600>;
				status = "ok";
			};

			mag2 {
				compatible="huawei,yamaha-yas537";
				reg=<0x2E>;
				chip_id_register=<0x80>;
				chip_id_value=<0x07>;
				file_id=<66>;
				sensor_list_info_id=<1>;
				sensor_type="mag";
				/*sensor-vdd-supply = <&ldo24>;*/
				outbit=<0>;
				softfilter = <2>;
				calibrate_method=<2>;
				axis_map_x=<0>;
				axis_map_y=<1>;
				axis_map_z=<2>;
				negate_x=<1>;
				negate_y=<0>;
				negate_z=<1>;
				poll_interval=<10>;
				gpio_int1=<&gpio0 0 0>;
				gpio_reset=<&gpio0 0 0>;
				softiron_parameter = <16 39 0 0 0 0 0 0 16 39 0 0 0 0 0 0 16 39 0 0 0 0 0 0 0 0 0>;
				sensorlist_name="mag-yas537";
				vendor="yamaha";
				minDelay=<10000>;
				fifoReservedEventCount=<600>;
				fifoMaxEventCount=<600>;
				status = "ok";
			};

			mag3 {
				compatible="huawei,akm-akm09918";
				reg=<0x0C>;
				chip_id_register=<0x00>;
				chip_id_value=<0x48>;
				file_id=<67>;
				sensor_list_info_id=<1>;
				sensor_type="mag";
				/*sensor-vdd-supply = <&ldo24>;*/
				outbit=<0>;
				calibrate_method=<2>;
				axis_map_x=<0>;
				axis_map_y=<1>;
				axis_map_z=<2>;
				negate_x=<1>;
				negate_y=<0>;
				negate_z=<1>;
				poll_interval=<10>;
				gpio_int1=<&gpio0 0 0>;
				gpio_reset=<&gpio0 0 0>;
				softiron_parameter = <16 39 0 0 0 0 0 0 16 39 0 0 0 0 0 0 16 39 0 0 0 0 0 0 0 0 0>;
				sensorlist_name="akm-akm09918";
				vendor="akm";
				minDelay=<10000>;
				fifoReservedEventCount=<600>;
				fifoMaxEventCount=<600>;
				status = "ok";
			};
		};

		airpress_sensor: airpress {
			airpress1 {
				compatible="huawei,st_lps22bh";
				reg=<0x5d>;
				status = "ok";
			};

			airpress2 {
				compatible="huawei,bosch_bmp380";
				reg=<0x77>;
				status = "ok";
			};
		};

		fingerprint_sensor: fingerprint {
			finger1 {
				compatible="fpc,fpc1075";
				reg=<0x0>;
				status = "ok";
			};

			finger2 {
				compatible="goodix,goodix3288";
				reg=<0x0>;
				status = "ok";
			};

			finger3 {
				compatible="silead,silead6185";
				reg=<0x0>;
				status = "ok";
			};
		};

		sar_sensor: sar {
			sar1 {
				compatible="huawei,semtech-sx9323";
				reg=<0x28>;
				status = "disabled";
			};

			sar2 {
				compatible="huawei,adi-adux1050";
				reg=<0x2c>;
				status = "disabled";
			};
		};
	};

        huawei_aod: aod {
                 compatible = "huawei,aod";
                 status="ok";
	};

	sensorhub_ext_config: sensorhub_ex {
		compatible = "huawei,sensorhub";
	};

	sensorhub_io_power: sensorhub_io_power {
		compatible = "huawei,sensorhub_io";
		status="ok";
	};

	hall: hall {
		compatible = "huawei,hall_sensor,ak8789";
		status = "ok";

		huawei,hall_0 {
		};
	};

	/*
		device check : the 0 means that it don't need to check;
			the 1 means that it check at board check and running test;
			the 2 means that it check at running test
	*/
	devcheck: devcheck {
		touch_panel = <2>;
		compass = <1>;
		g_sensor = <1>;
		gyroscope = <1>;
		nfc = <1>;
		dc_dc = <0>;
		tps = <1>;
		l_sensor = <2>;
		charge = <1>;
		usb_switch = <0>;
		wifi = <1>;
		bt = <1>;
		gps = <1>;
		antenna_ctl = <0>;
		airpress = <1>;
		vibrator_lra = <1>;
		charge_loadswitch = <1>;
		laser = <1>;
		status = "ok";
	};

	huawei_hisi_isp160: huawei,hisi_isp160 {
                status = "ok";
	};

	huawei_hjpeg: huawei,hjpeg {
		compatible = "huawei,hjpeg";
		reg = <0 0xE8300000 0 0x1000>;
		status = "ok";
	};

	huawei_hisi_fd: huawei,hisi_fd {
		compatible = "hisilicon,hisi-fd";
		reg = <0x0 0xE8340000 0x0 0x20000>,    //FD reg
		      <0x0 0xE8320000 0x0 0x20000>,    //smmu reg
		      <0x0 0xE8303000 0x0 0x1000>;    //smmu master reg

		status = "ok";
	};

	hisi_hisi_camera: hisi,hisi_camera {
	};

	huawei_imx486hybird: huawei,imx486hybird {
		compatible = "huawei,imx486hybird_ab";
		status = "disable";
	};

	huawei_imx319: huawei,imx319 {
		compatible = "huawei,imx319_ab";
		status = "ok";
	};

	huawei_imx386hybird: huawei,imx386hybird {
		compatible = "huawei,imx386hybird_ab";
		status = "ok";
	};

	huawei_camera_ldo: huawei,camera_ldo {
	};

	bcm_wifi: bcm_wifi {
		compatible = "hisilicon,bcm_wifi";
		status = "ok";
	};

	bcm_bt: bcm_bt {
		compatible = "hisilicon,bcm_bt";
		status = "ok";
	};

	fingerprint: fingerprint {
		compatible = "fpc,fingerprint";
		spi-max-frequency = <5000000>;
		fingerprint,product = "blanc";

		fingerprint,navigation_adjust1 = <0>;
		fingerprint,navigation_adjust2 = <0>;

		fingerprint,fpc2050 = <1>;
		fingerprint,reset_gpio = <211>;
		fingerprint,irq_gpio = <210>;
		fingerprint,cs_gpio = <216>;
		fingerprint,spi_num = <2>;
		fingerprint,force_storage_type = <1>;
		fingerprint,extern_ldo_name = "EXTERN_LDO";
		fingerprint,extern_ldo_num = <34>;
		fingreprint_ldo-supply = <&ldo34>;
		fingerprint,extern_vol = <3300000>;
		pinctrl-names = "default", "idle";
	};

	irda: irda {
		compatible = "irda,config";
	};

	irda_maxim: irda_maxim {
		status = "ok";
	};

        bluetooth_power: bluetooth_power {
                status = "ok";
        };


    
    spmi: spmi@FFF24000 {
        pmic: pmic@0 {
            sim0 {
                gpios = <&gpio25 5 0>;
                sim_id = <0>;
                status = "ok";
                func_sel_state = "not_use_multi_func";
                det_normal_direction = "closed";
                allocate_gpio = <1>;
                shared_det_irq = <1>;
                send_msg_to_cp = <1>;
                card_tray_style = <1>;
                hpd_interrupt_to_close_ldo = <0x0A>;
                hpd_debounce_wait_time = <0x00>;
                det_debounce_wait_time = <300>;
                interrupt-parent = <&pmic>;
                interrupts = <11 0>;
                interrupt-names = "hpd0_falling";
                pmu_status1_address = <0x007>;
                pmu_ldo11_onoff_eco_address = <0x01D>;
                pmu_ldo11_vset_address = <0x058>;
                pmu_ldo12_onoff_eco_address = <0x01E>;
                pmu_ldo12_vset_address = <0x059>;
                pmu_sim_ctrl_address = <0x169>;
                pmu_sim_deb_ctrl_address = <0x16B>;
                pmu_irq_mask3_address = <0x203>;
                pmu_irq3_address = <0x213>;
                pmu_ldo11_onoff_value = <0x03>;
                pmu_ldo11_vset_value = <0x01>;
                pmu_ldo12_onoff_value = <0x03>;
                pmu_ldo12_vset_value = <0x01>;
                send_card_out_msg_when_init = <0>;
            };

            sim1 {
                gpios = <&gpio25 5 0>;
                sim_id = <1>;
                status = "ok";
		};
        };
    };
    
	jtagtosd {
		not_always_on;
	};
};
